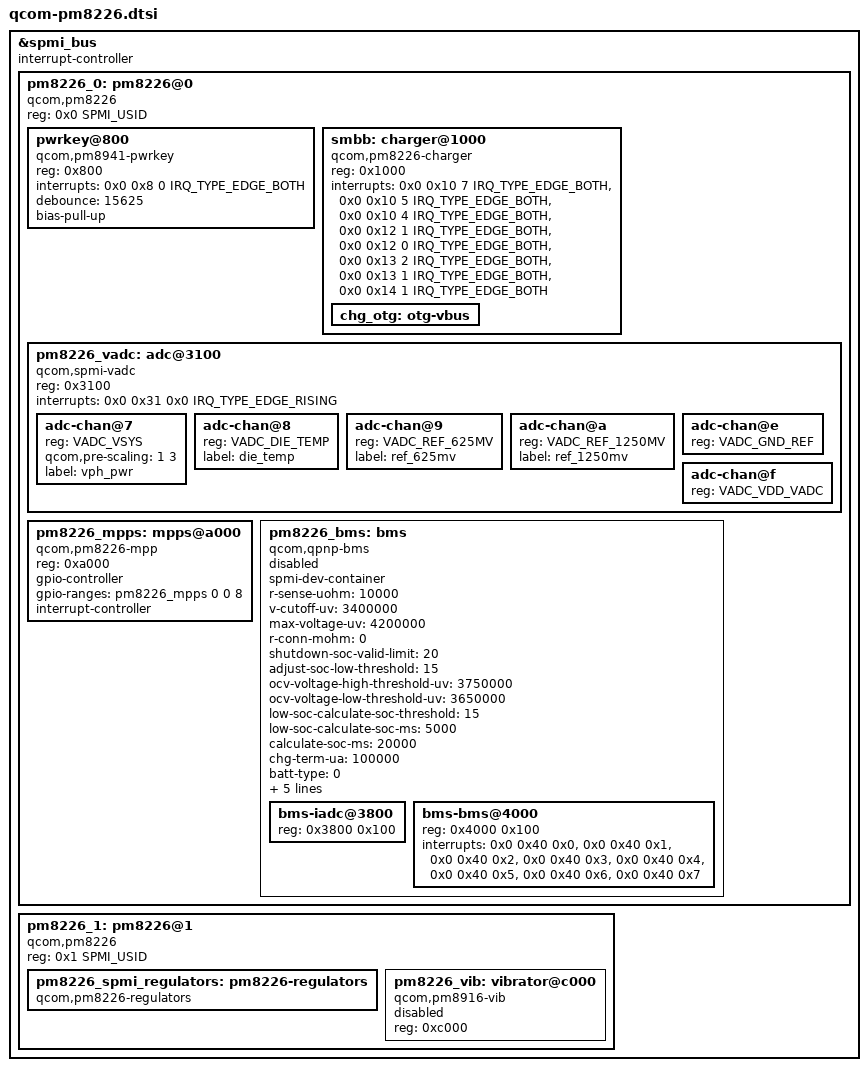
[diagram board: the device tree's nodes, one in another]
// SPDX-License-Identifier: BSD-3-Clause
#include <dt-bindings/interrupt-controller/irq.h>
#include <dt-bindings/spmi/spmi.h>
#include <dt-bindings/iio/qcom,spmi-vadc.h>

&spmi_bus {
	#address-cells = <1>;
	#size-cells = <0>;
	interrupt-controller;
	#interrupt-cells = <3>;

	pm8226_0: pm8226@0 {
		compatible = "qcom,pm8226", "qcom,spmi-pmic";
		reg = <0x0 SPMI_USID>;
		#address-cells = <1>;
		#size-cells = <0>;

		pwrkey@800 {
			compatible = "qcom,pm8941-pwrkey";
			reg = <0x800>;
			interrupts = <0x0 0x8 0 IRQ_TYPE_EDGE_BOTH>;
			debounce = <15625>;
			bias-pull-up;
		};

		smbb: charger@1000 {
			compatible = "qcom,pm8226-charger";
			reg = <0x1000>;
			interrupts = <0x0 0x10 7 IRQ_TYPE_EDGE_BOTH>,
				     <0x0 0x10 5 IRQ_TYPE_EDGE_BOTH>,
				     <0x0 0x10 4 IRQ_TYPE_EDGE_BOTH>,
				     <0x0 0x12 1 IRQ_TYPE_EDGE_BOTH>,
				     <0x0 0x12 0 IRQ_TYPE_EDGE_BOTH>,
				     <0x0 0x13 2 IRQ_TYPE_EDGE_BOTH>,
				     <0x0 0x13 1 IRQ_TYPE_EDGE_BOTH>,
				     <0x0 0x14 1 IRQ_TYPE_EDGE_BOTH>;
			interrupt-names = "chg-done",
					  "chg-fast",
					  "chg-trkl",
					  "bat-temp-ok",
					  "bat-present",
					  "chg-gone",
					  "usb-valid",
					  "dc-valid";

			chg_otg: otg-vbus { };
		};

		pm8226_vadc: adc@3100 {
			compatible = "qcom,spmi-vadc";
			reg = <0x3100>;
			interrupts = <0x0 0x31 0x0 IRQ_TYPE_EDGE_RISING>;
			#address-cells = <1>;
			#size-cells = <0>;
			#io-channel-cells = <1>;

			adc-chan@7 {
				reg = <VADC_VSYS>;
				qcom,pre-scaling = <1 3>;
				label = "vph_pwr";
			};
			adc-chan@8 {
				reg = <VADC_DIE_TEMP>;
				label = "die_temp";
			};
			adc-chan@9 {
				reg = <VADC_REF_625MV>;
				label = "ref_625mv";
			};
			adc-chan@a {
				reg = <VADC_REF_1250MV>;
				label = "ref_1250mv";
			};
			adc-chan@e {
				reg = <VADC_GND_REF>;
			};
			adc-chan@f {
				reg = <VADC_VDD_VADC>;
			};
		};

		pm8226_mpps: mpps@a000 {
			compatible = "qcom,pm8226-mpp", "qcom,spmi-mpp";
			reg = <0xa000>;
			gpio-controller;
			#gpio-cells = <2>;
			gpio-ranges = <&pm8226_mpps 0 0 8>;
			interrupt-controller;
			#interrupt-cells = <2>;
		};

		pm8226_bms: bms {
			spmi-dev-container;
			compatible = "qcom,qpnp-bms";
			#address-cells = <1>;
			#size-cells = <1>;
			status = "disabled";

			r-sense-uohm = <10000>;
			v-cutoff-uv = <3400000>;
			max-voltage-uv = <4200000>;
			r-conn-mohm = <0>;
			shutdown-soc-valid-limit = <20>;
			adjust-soc-low-threshold = <15>;
			ocv-voltage-high-threshold-uv = <3750000>;
			ocv-voltage-low-threshold-uv = <3650000>;
			low-soc-calculate-soc-threshold = <15>;
			low-soc-calculate-soc-ms = <5000>;
			calculate-soc-ms = <20000>;
			chg-term-ua = <100000>;
			batt-type = <0>;
			tm-temp-margin = <5000>;
			low-ocv-correction-limit-uv = <100>;
			high-ocv-correction-limit-uv = <50>;
			hold-soc-est = <3>;
			low-voltage-threshold = <3420000>;

			bms-iadc@3800 {
				reg = <0x3800 0x100>;
			};

			bms-bms@4000 {
				reg = <0x4000 0x100>;
				interrupts =	<0x0 0x40 0x0>,
						<0x0 0x40 0x1>,
						<0x0 0x40 0x2>,
						<0x0 0x40 0x3>,
						<0x0 0x40 0x4>,
						<0x0 0x40 0x5>,
						<0x0 0x40 0x6>,
						<0x0 0x40 0x7>;

				interrupt-names = "vsense_for_r",
						  "vsense_avg",
						  "sw_cc_thr",
						  "ocv_thr",
						  "charge_begin",
						  "good_ocv",
						  "ocv_for_r",
						  "cc_thr";
			};
		};
	};

	pm8226_1: pm8226@1 {
		compatible = "qcom,pm8226", "qcom,spmi-pmic";
		reg = <0x1 SPMI_USID>;
		#address-cells = <1>;
		#size-cells = <0>;

		pm8226_spmi_regulators: pm8226-regulators {
			compatible = "qcom,pm8226-regulators";
		};

		pm8226_vib: vibrator@c000 {
			compatible = "qcom,pm8916-vib";
			reg = <0xc000>;
			status = "disabled";
		};
	};
};
